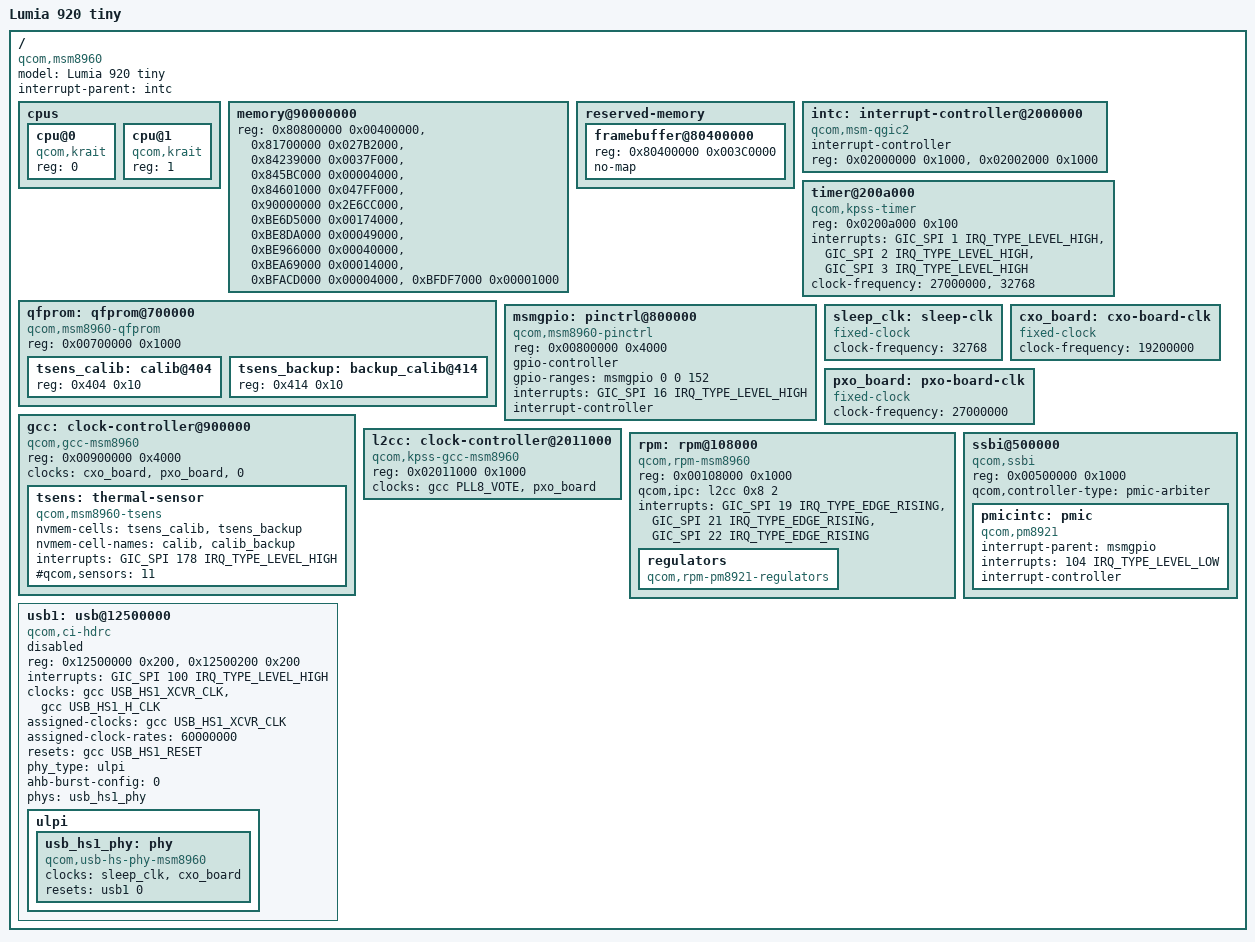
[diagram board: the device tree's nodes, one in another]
/dts-v1/;

#include <dt-bindings/interrupt-controller/arm-gic.h>
#include <dt-bindings/clock/qcom,gcc-msm8960.h>
#include <dt-bindings/reset/qcom,gcc-msm8960.h>

/ {
    model = "Lumia 920 tiny";
	compatible = "qcom,msm8960";

    #address-cells = <1>;
    #size-cells = <1>;

    interrupt-parent = <&intc>;

    cpus {
        cpu@0 {
            device_type = "cpu";
            compatible = "qcom,krait";
            reg = <0>;
        };
        cpu@1 {
            device_type = "cpu";
            compatible = "qcom,krait";
            reg = <1>;
        };
    };

    memory@90000000 {
        device_type = "memory";

        reg = <0x80800000 0x00400000>,
              <0x81700000 0x027B2000>,
              <0x84239000 0x0037F000>,
              <0x845BC000 0x00004000>,
              <0x84601000 0x047FF000>,
              <0x90000000 0x2E6CC000>,
              <0xBE6D5000 0x00174000>,
              <0xBE8DA000 0x00049000>,
              <0xBE966000 0x00040000>,
              <0xBEA69000 0x00014000>,
              <0xBFACD000 0x00004000>,
              <0xBFDF7000 0x00001000>;
    };

    reserved-memory {
        #address-cells = <1>;
        #size-cells = <1>;
        ranges;

        framebuffer@80400000 {
            reg = <0x80400000 0x003C0000>;
            no-map;
        };
    };

    intc: interrupt-controller@2000000 {
        compatible = "qcom,msm-qgic2";

        interrupt-controller;
        #interrupt-cells = <3>;

        reg =
            <0x02000000 0x1000>,
            <0x02002000 0x1000>;
    };

    timer@200a000 {
        compatible =
            "qcom,kpss-timer",
            "qcom,msm-timer";
        reg = <0x0200a000 0x100>;
        interrupts = 
            <GIC_SPI 1 IRQ_TYPE_LEVEL_HIGH>,
            <GIC_SPI 2 IRQ_TYPE_LEVEL_HIGH>,
            <GIC_SPI 3 IRQ_TYPE_LEVEL_HIGH>;
        clock-frequency =
            <27000000>,
            <32768>;
    };

    // QFPROM

    qfprom: qfprom@700000 {
        compatible = "qcom,msm8960-qfprom", "qcom,qfprom";
        reg = <0x00700000 0x1000>;

        #address-cells = <1>;
        #size-cells = <1>;
        ranges;

        tsens_calib: calib@404 {
            reg = <0x404 0x10>;
        };

        tsens_backup: backup_calib@414 {
            reg = <0x414 0x10>;
        };
    };

    // GPIO

    msmgpio: pinctrl@800000 {
        compatible = "qcom,msm8960-pinctrl";

        reg = <0x00800000 0x4000>;

        gpio-controller;
        #gpio-cells = <2>;

        gpio-ranges = <&msmgpio 0 0 152>;

        interrupts = <GIC_SPI 16 IRQ_TYPE_LEVEL_HIGH>;

        interrupt-controller;
        #interrupt-cells = <2>;
    };

    // clock sources for external devices

    sleep_clk: sleep-clk {
        compatible = "fixed-clock";
        #clock-cells = <0>;
        clock-frequency = <32768>;
    };

    cxo_board: cxo-board-clk {
        compatible = "fixed-clock";
        #clock-cells = <0>;
        clock-frequency = <19200000>;
    };

    pxo_board: pxo-board-clk {
        compatible = "fixed-clock";
        #clock-cells = <0>;
        clock-frequency = <27000000>;
    };

    gcc: clock-controller@900000 {
        compatible = "qcom,gcc-msm8960", "syscon";
        reg = <0x00900000 0x4000>;

        #clock-cells = <1>;
        #reset-cells = <1>;
        #power-domain-cells = <1>;

        clocks = <&cxo_board>, <&pxo_board>, <0>;
        clock-names = "cxo", "pxo", "pll4";

        tsens: thermal-sensor {
            compatible = "qcom,msm8960-tsens";

            nvmem-cells = <&tsens_calib>, <&tsens_backup>;
            nvmem-cell-names = "calib", "calib_backup";

            interrupts = <GIC_SPI 178 IRQ_TYPE_LEVEL_HIGH>;
            interrupt-names = "uplow";

            #qcom,sensors = <11>;
            #thermal-sensor-cells = <1>;
        };
    };

    l2cc: clock-controller@2011000 {
        compatible = "qcom,kpss-gcc-msm8960", "qcom,kpss-gcc", "syscon";
        reg = <0x02011000 0x1000>;

        clocks = <&gcc PLL8_VOTE>, <&pxo_board>;
        clock-names = "pll8_vote", "pxo";

        #clock-cells = <0>;
    };

    // PMIC

    rpm: rpm@108000 {
        compatible = "qcom,rpm-msm8960";
        reg = <0x00108000 0x1000>;

        qcom,ipc = <&l2cc 0x8 2>;

        status = "okay";

        interrupts = <GIC_SPI 19 IRQ_TYPE_EDGE_RISING>,
                     <GIC_SPI 21 IRQ_TYPE_EDGE_RISING>,
                     <GIC_SPI 22 IRQ_TYPE_EDGE_RISING>;
        interrupt-names = "ack", "err", "wakeup";

        regulators {
            compatible = "qcom,rpm-pm8921-regulators";
        };
    };

    ssbi@500000 {
        compatible = "qcom,ssbi";
        reg = <0x00500000 0x1000>;

        qcom,controller-type = "pmic-arbiter";

        pmicintc: pmic {
            compatible = "qcom,pm8921";

            interrupt-parent = <&msmgpio>;
            interrupts = <104 IRQ_TYPE_LEVEL_LOW>;

            interrupt-controller;
            #interrupt-cells = <2>;

            #address-cells = <1>;
            #size-cells = <0>;

            status = "okay";
        };
    };

    // USB

    usb1: usb@12500000 {
        compatible = "qcom,ci-hdrc";
        reg = <0x12500000 0x200>,
              <0x12500200 0x200>;
        interrupts = <GIC_SPI 100 IRQ_TYPE_LEVEL_HIGH>;

        clocks = <&gcc USB_HS1_XCVR_CLK>,
             <&gcc USB_HS1_H_CLK>;
        clock-names = "core", "iface";

        assigned-clocks = <&gcc USB_HS1_XCVR_CLK>;
        assigned-clock-rates = <60000000>;

        resets = <&gcc USB_HS1_RESET>;
        reset-names = "core";

        phy_type = "ulpi";
        ahb-burst-config = <0>;

        phys = <&usb_hs1_phy>;
        phy-names = "usb-phy";

        #reset-cells = <1>;
        status = "disabled";

        ulpi {
            usb_hs1_phy: phy {
                compatible = "qcom,usb-hs-phy-msm8960",
                             "qcom,usb-hs-phy";

                clocks = <&sleep_clk>, <&cxo_board>;
                clock-names = "sleep", "ref";

                resets = <&usb1 0>;
                reset-names = "por";

                #phy-cells = <0>;
            };
        };
    };
};
